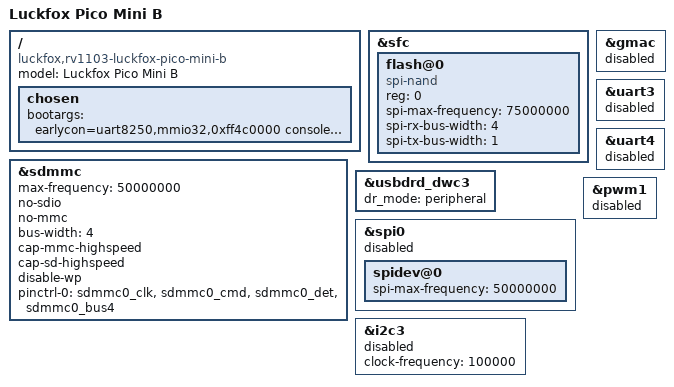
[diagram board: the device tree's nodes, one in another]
// SPDX-License-Identifier: (GPL-2.0+ OR MIT)
/*
 * Copyright (c) 2023 Luckfox Electronics Co., Ltd.
 */

/dts-v1/;

#include "rv1103.dtsi"
#include "rv1106-evb.dtsi"
#include "rv1103-luckfox-pico-ipc.dtsi"

/ {
	model = "Luckfox Pico Mini B";
	compatible = "luckfox,rv1103-luckfox-pico-mini-b", "rockchip,rv1103";

	chosen {
		bootargs = "earlycon=uart8250,mmio32,0xff4c0000 console=ttyS2,1500000n8 mtdparts=spi2.0:256K(env),256K@256K(idblock),512K(uboot),6M@1280K(boot),-(ubi) ubi.mtd=ubi ubi.block=0,rootfs root=/dev/ubiblock0_0 rootfstype=squashfs ro rootwait rk_dma_heap_cma=24M";
	};
};

/**********SFC**********/
/* Luckfox Pico Mini B has 128MB SPI NAND */
&sfc {
	status = "okay";
	flash@0 {
		compatible = "spi-nand";
		reg = <0>;
		spi-max-frequency = <75000000>;
		spi-rx-bus-width = <4>;
		spi-tx-bus-width = <1>;
	};
};

/**********SDMMC**********/
&sdmmc {
	max-frequency = <50000000>;
	no-sdio;
	no-mmc;
	bus-width = <4>;
	cap-mmc-highspeed;
	cap-sd-highspeed;
	disable-wp;
	pinctrl-names = "default";
	pinctrl-0 = <&sdmmc0_clk &sdmmc0_cmd &sdmmc0_det &sdmmc0_bus4>;
	status = "okay";
};

/**********ETH**********/
&gmac {
	status = "disabled";
};

/**********USB**********/
&usbdrd_dwc3 {
	status = "okay";
	dr_mode = "peripheral";
};

/**********SPI**********/
/* SPI0_M0 */
&spi0 {
	status = "disabled";
	spidev@0 {
		spi-max-frequency = <50000000>;
	};
};

/**********I2C**********/
/* I2C3_M1 */
&i2c3 {
	status = "disabled";
	clock-frequency = <100000>;
};

/**********UART**********/
/* UART3_M1 */
&uart3 {
	status = "disabled";
};

/* UART4_M1 */
&uart4 {
	status = "disabled";
};

/**********PWM**********/
/* PWM1_M0 */
&pwm1 {
	status = "disabled";
};
